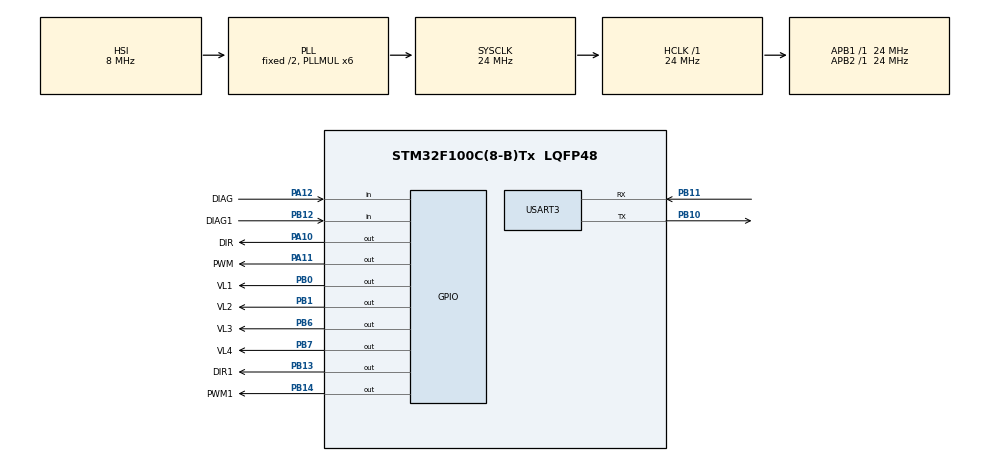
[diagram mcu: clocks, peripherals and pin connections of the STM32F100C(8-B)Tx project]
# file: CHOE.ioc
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Mcu.Family=STM32F1
Mcu.Name=STM32F100C(8-B)Tx
Mcu.Package=LQFP48
NVIC.PriorityGroup=NVIC_PRIORITYGROUP_4
PA10.GPIO_Label=DIR
PA10.Signal=GPIO_Output
PA11.GPIO_Label=PWM
PA11.Signal=GPIO_Output
PA12.GPIO_Label=DIAG
PA12.Signal=GPIO_Input
PA13.Mode=Trace_Asynchronous_SW
PA13.Signal=SYS_JTMS-SWDIO
PA14.Mode=Trace_Asynchronous_SW
PA14.Signal=SYS_JTCK-SWCLK
PB0.GPIO_Label=VL1
PB0.Signal=GPIO_Output
PB1.GPIO_Label=VL2
PB1.Signal=GPIO_Output
PB10.Mode=Asynchronous
PB10.Signal=USART3_TX
PB11.Mode=Asynchronous
PB11.Signal=USART3_RX
PB12.GPIO_Label=DIAG1
PB12.Signal=GPIO_Input
PB13.GPIO_Label=DIR1
PB13.Signal=GPIO_Output
PB14.GPIO_Label=PWM1
PB14.Signal=GPIO_Output
PB3.Mode=Trace_Asynchronous_SW
PB3.Signal=SYS_JTDO-TRACESWO
PB6.GPIO_Label=VL3
PB6.Signal=GPIO_Output
PB7.GPIO_Label=VL4
PB7.Signal=GPIO_Output
ProjectManager.HeapSize=0x200
ProjectManager.StackSize=0x400
ProjectManager.TargetToolchain=STM32CubeIDE
RCC.AHBFreq_Value=24000000
RCC.APB1Freq_Value=24000000
RCC.APB1TimFreq_Value=24000000
RCC.APB2Freq_Value=24000000
RCC.APB2TimFreq_Value=24000000
RCC.HCLKFreq_Value=24000000
RCC.PLLMUL=RCC_PLL_MUL6
RCC.SYSCLKFreq_VALUE=24000000
RCC.SYSCLKSource=RCC_SYSCLKSOURCE_PLLCLK
USART3.VirtualMode=VM_ASYNC
board=custom

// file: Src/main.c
/* USER CODE BEGIN Header */
/**
  ******************************************************************************
  * @file           : main.c
  * @brief          : Main program body
  ******************************************************************************
  * @attention
  *
  * <h2><center>&copy; Copyright (c) 2021 STMicroelectronics.
  * All rights reserved.</center></h2>
  *
  * This software component is licensed by ST under BSD 3-Clause license,
  * the "License"; You may not use this file except in compliance with the
  * License. You may obtain a copy of the License at:
  *                        opensource.org/licenses/BSD-3-Clause
  *
  ******************************************************************************
  */
/* USER CODE END Header */

#include "main.h"

UART_HandleTypeDef huart3;

void SystemClock_Config(void);
static void MX_GPIO_Init(void);
static void MX_USART3_UART_Init(void);

int main(void)
{
	/* USER CODE BEGIN 1 */
	char buffer[2];
	HAL_StatusTypeDef res;
	/* USER CODE END 1 */

	/* MCU Configuration--------------------------------------------------------*/

	/* Reset of all peripherals, Initializes the Flash interface and the Systick. */
	HAL_Init();

	/* Configure the system clock */
	SystemClock_Config();

	/* Initialize all configured peripherals */
	MX_GPIO_Init();
	MX_USART3_UART_Init();

	/* Infinite loop */
	/* USER CODE BEGIN WHILE */
	while (1)
	{
		//HAL_UART_Transmit(&huart3, "hhh", 3, 10);
		res=HAL_UART_Receive(&huart3, buffer, 1, 100);
		if(res==HAL_OK)
		{
			switch(buffer[0])
			{
				case 'A':
					HAL_GPIO_WritePin(GPIOB, VL1_Pin, GPIO_PIN_SET);
					break;

				case 'B':
					HAL_GPIO_WritePin(GPIOB, VL2_Pin, GPIO_PIN_SET);
					break;

				case 'C':
					HAL_GPIO_WritePin(GPIOB, VL3_Pin, GPIO_PIN_SET);
					break;

				case 'D':
					HAL_GPIO_WritePin(GPIOB, VL4_Pin, GPIO_PIN_SET);
					break;

				case 'E':
					HAL_GPIO_WritePin(GPIOA, DIR_Pin, GPIO_PIN_SET);
					HAL_GPIO_WritePin(GPIOA, PWM_Pin, GPIO_PIN_SET);
					HAL_Delay(200);
					HAL_GPIO_WritePin(GPIOA, DIR_Pin, GPIO_PIN_RESET);
					HAL_GPIO_WritePin(GPIOA, PWM_Pin, GPIO_PIN_RESET);
					break;

				case 'F':
					HAL_GPIO_WritePin(GPIOB, PWM1_Pin, GPIO_PIN_SET);
					HAL_Delay(200);
					HAL_GPIO_WritePin(GPIOB, PWM1_Pin, GPIO_PIN_RESET);
					break;

				case 'a':
					HAL_GPIO_WritePin(GPIOB, VL1_Pin, GPIO_PIN_RESET);
					break;

				case 'b':
					HAL_GPIO_WritePin(GPIOB, VL2_Pin, GPIO_PIN_RESET);
					break;

				case 'c':
					HAL_GPIO_WritePin(GPIOB, VL3_Pin, GPIO_PIN_RESET);
					break;

				case 'd':
					HAL_GPIO_WritePin(GPIOB, VL4_Pin, GPIO_PIN_RESET);
					break;

				case 'e':
					HAL_GPIO_WritePin(GPIOA, DIR_Pin, GPIO_PIN_SET);
					HAL_GPIO_WritePin(GPIOA, PWM_Pin, GPIO_PIN_SET);
					HAL_Delay(200);
					HAL_GPIO_WritePin(GPIOA, DIR_Pin, GPIO_PIN_RESET);
					HAL_GPIO_WritePin(GPIOA, PWM_Pin, GPIO_PIN_RESET);
					break;

				case 'f':
					HAL_GPIO_WritePin(GPIOB, PWM1_Pin, GPIO_PIN_SET);
					HAL_Delay(200);
					HAL_GPIO_WritePin(GPIOB, PWM1_Pin, GPIO_PIN_RESET);
					break;

				default :
					break;
			}
		}
	}
  /* USER CODE END 3 */
}

void SystemClock_Config(void)
{
  RCC_OscInitTypeDef RCC_OscInitStruct = {0};
  RCC_ClkInitTypeDef RCC_ClkInitStruct = {0};

  /** Initializes the CPU, AHB and APB busses clocks
  */
  RCC_OscInitStruct.OscillatorType = RCC_OSCILLATORTYPE_HSI;
  RCC_OscInitStruct.HSIState = RCC_HSI_ON;
  RCC_OscInitStruct.HSICalibrationValue = RCC_HSICALIBRATION_DEFAULT;
  RCC_OscInitStruct.PLL.PLLState = RCC_PLL_ON;
  RCC_OscInitStruct.PLL.PLLSource = RCC_PLLSOURCE_HSI_DIV2;
  RCC_OscInitStruct.PLL.PLLMUL = RCC_PLL_MUL6;
  if (HAL_RCC_OscConfig(&RCC_OscInitStruct) != HAL_OK)
  {
    Error_Handler();
  }
  /** Initializes the CPU, AHB and APB busses clocks
  */
  RCC_ClkInitStruct.ClockType = RCC_CLOCKTYPE_HCLK|RCC_CLOCKTYPE_SYSCLK
                              |RCC_CLOCKTYPE_PCLK1|RCC_CLOCKTYPE_PCLK2;
  RCC_ClkInitStruct.SYSCLKSource = RCC_SYSCLKSOURCE_PLLCLK;
  RCC_ClkInitStruct.AHBCLKDivider = RCC_SYSCLK_DIV1;
  RCC_ClkInitStruct.APB1CLKDivider = RCC_HCLK_DIV1;
  RCC_ClkInitStruct.APB2CLKDivider = RCC_HCLK_DIV1;

  if (HAL_RCC_ClockConfig(&RCC_ClkInitStruct, FLASH_LATENCY_0) != HAL_OK)
  {
    Error_Handler();
  }
}

static void MX_USART3_UART_Init(void)
{

  huart3.Instance = USART3;
  huart3.Init.BaudRate = 115200;
  huart3.Init.WordLength = UART_WORDLENGTH_8B;
  huart3.Init.StopBits = UART_STOPBITS_1;
  huart3.Init.Parity = UART_PARITY_NONE;
  huart3.Init.Mode = UART_MODE_TX_RX;
  huart3.Init.HwFlowCtl = UART_HWCONTROL_NONE;
  huart3.Init.OverSampling = UART_OVERSAMPLING_16;
  if (HAL_UART_Init(&huart3) != HAL_OK)
  {
    Error_Handler();
  }

}

static void MX_GPIO_Init(void)
{
  GPIO_InitTypeDef GPIO_InitStruct = {0};

  /* GPIO Ports Clock Enable */
  __HAL_RCC_GPIOB_CLK_ENABLE();
  __HAL_RCC_GPIOA_CLK_ENABLE();

  /*Configure GPIO pin Output Level */
  HAL_GPIO_WritePin(GPIOB, VL1_Pin|VL2_Pin|DIR1_Pin|PWM1_Pin
                          |VL3_Pin|VL4_Pin, GPIO_PIN_RESET);

  /*Configure GPIO pin Output Level */
  HAL_GPIO_WritePin(GPIOA, DIR_Pin|PWM_Pin, GPIO_PIN_RESET);

  /*Configure GPIO pins : VL1_Pin VL2_Pin DIR1_Pin PWM1_Pin
                           VL3_Pin VL4_Pin */
  GPIO_InitStruct.Pin = VL1_Pin|VL2_Pin|DIR1_Pin|PWM1_Pin
                          |VL3_Pin|VL4_Pin;
  GPIO_InitStruct.Mode = GPIO_MODE_OUTPUT_PP;
  GPIO_InitStruct.Pull = GPIO_NOPULL;
  GPIO_InitStruct.Speed = GPIO_SPEED_FREQ_LOW;
  HAL_GPIO_Init(GPIOB, &GPIO_InitStruct);

  /*Configure GPIO pin : DIAG1_Pin */
  GPIO_InitStruct.Pin = DIAG1_Pin;
  GPIO_InitStruct.Mode = GPIO_MODE_INPUT;
  GPIO_InitStruct.Pull = GPIO_NOPULL;
  HAL_GPIO_Init(DIAG1_GPIO_Port, &GPIO_InitStruct);

  /*Configure GPIO pins : DIR_Pin PWM_Pin */
  GPIO_InitStruct.Pin = DIR_Pin|PWM_Pin;
  GPIO_InitStruct.Mode = GPIO_MODE_OUTPUT_PP;
  GPIO_InitStruct.Pull = GPIO_NOPULL;
  GPIO_InitStruct.Speed = GPIO_SPEED_FREQ_LOW;
  HAL_GPIO_Init(GPIOA, &GPIO_InitStruct);

  /*Configure GPIO pin : DIAG_Pin */
  GPIO_InitStruct.Pin = DIAG_Pin;
  GPIO_InitStruct.Mode = GPIO_MODE_INPUT;
  GPIO_InitStruct.Pull = GPIO_NOPULL;
  HAL_GPIO_Init(DIAG_GPIO_Port, &GPIO_InitStruct);

}

void Error_Handler(void)
{
}

/************************ (C) COPYRIGHT STMicroelectronics *****END OF FILE****/
